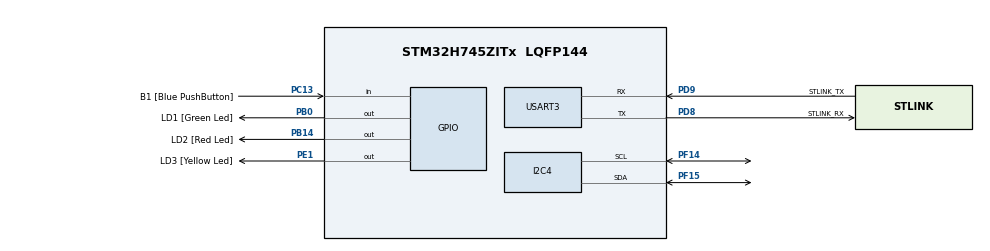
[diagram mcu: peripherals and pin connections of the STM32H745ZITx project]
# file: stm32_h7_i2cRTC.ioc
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CortexM4.IPs=BDMA,CORTEX_M4\:I,DEBUG,DMA,FATFS_M4\:I,FREERTOS_M4\:I,GPIO,IWDG2\:I,MDMA,NVIC2\:I,OPENAMP_M4\:I,PDM2PCM_M4\:I,PWR,RCC,RESMGR_UTILITY,SYS_M4\:I,USB_DEVICE_M4\:I,USB_HOST_M4\:I,VREFBUF,WWDG2\:I,USART3,I2C4
CortexM4.Pins=PE1
CortexM7.IPs=BDMA\:I,CORTEX_M7\:I,DEBUG\:I,DMA\:I,FATFS_M7\:I,FREERTOS_M7\:I,GPIO\:I,IWDG1\:I,MDMA\:I,NVIC1\:I,OPENAMP_M7\:I,PDM2PCM_M7\:I,PWR\:I,RCC\:I,RESMGR_UTILITY\:I,SYS\:I,USB_DEVICE_M7\:I,USB_HOST_M7\:I,VREFBUF\:I,WWDG1\:I,USART3\:I,I2C4\:I
CortexM7.Pins=PC13,PB0,PB14
I2C4.Timing=0x307075B1
Mcu.Family=STM32H7
Mcu.Name=STM32H745ZITx
Mcu.Package=LQFP144
NVIC1.PriorityGroup=NVIC_PRIORITYGROUP_4
NVIC2.PriorityGroup=NVIC_PRIORITYGROUP_4
PA13\ (JTMS/SWDIO).Mode=Serial_Wire
PA13\ (JTMS/SWDIO).PinAttribute=CortexM7
PA13\ (JTMS/SWDIO).Signal=DEBUG_JTMS-SWDIO
PA14\ (JTCK/SWCLK).Mode=Serial_Wire
PA14\ (JTCK/SWCLK).PinAttribute=CortexM7
PA14\ (JTCK/SWCLK).Signal=DEBUG_JTCK-SWCLK
PB0.GPIO_Label=LD1 [Green Led]
PB0.PinAttribute=CortexM7
PB0.Signal=GPIO_Output
PB14.GPIO_Label=LD2 [Red Led]
PB14.PinAttribute=CortexM7
PB14.Signal=GPIO_Output
PC13.GPIO_Label=B1 [Blue PushButton]
PC13.PinAttribute=CortexM7
PC13.Signal=GPIO_Input
PC14-OSC32_IN\ (OSC32_IN).Mode=LSE-External-Oscillator
PC14-OSC32_IN\ (OSC32_IN).PinAttribute=CortexM7
PC14-OSC32_IN\ (OSC32_IN).Signal=RCC_OSC32_IN
PC15-OSC32_OUT\ (OSC32_OUT).Mode=LSE-External-Oscillator
PC15-OSC32_OUT\ (OSC32_OUT).PinAttribute=CortexM7
PC15-OSC32_OUT\ (OSC32_OUT).Signal=RCC_OSC32_OUT
PD8.GPIO_Label=STLINK_RX
PD8.Mode=Asynchronous
PD8.PinAttribute=CortexM7
PD8.Signal=USART3_TX
PD9.GPIO_Label=STLINK_TX
PD9.Mode=Asynchronous
PD9.PinAttribute=CortexM7
PD9.Signal=USART3_RX
PE1.GPIO_Label=LD3 [Yellow Led]
PE1.PinAttribute=CortexM4
PE1.Signal=GPIO_Output
PF14.Mode=I2C
PF14.PinAttribute=CortexM7
PF14.Signal=I2C4_SCL
PF15.Mode=I2C
PF15.PinAttribute=CortexM7
PF15.Signal=I2C4_SDA
PH0-OSC_IN\ (PH0).Mode=HSE-External-Clock-Source
PH0-OSC_IN\ (PH0).PinAttribute=CortexM7
PH0-OSC_IN\ (PH0).Signal=RCC_OSC_IN
ProjectManager.HeapSize=M4-0x200,M7-0x200
ProjectManager.StackSize=M4-0x400,M7-0x400
ProjectManager.TargetToolchain=STM32CubeIDE
RCC.ADCFreq_Value=16125000
RCC.APB1Freq_Value=120000000
RCC.APB2Freq_Value=120000000
RCC.APB3Freq_Value=120000000
RCC.APB4Freq_Value=120000000
RCC.CortexFreq_Value=480000000
RCC.D1PPRE=RCC_APB3_DIV2
RCC.D2PPRE1=RCC_APB1_DIV2
RCC.D2PPRE2=RCC_APB2_DIV2
RCC.D3PPRE=RCC_APB4_DIV2
RCC.DIVM1=2
RCC.DIVN1=240
RCC.HCLKFreq_Value=240000000
RCC.HPRE=RCC_HCLK_DIV2
RCC.HSE_VALUE=8000000
RCC.PLLSourceVirtual=RCC_PLLSOURCE_HSE
RCC.SYSCLKFreq_VALUE=480000000
RCC.SYSCLKSource=RCC_SYSCLKSOURCE_PLLCLK
RCC.USBFreq_Value=480000000
SYS.userName=SYS_M7
USART3.VirtualMode-Asynchronous=VM_ASYNC
VP_SYS_M4_VS_Systick.Mode=SysTick
board=custom

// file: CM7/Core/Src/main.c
/* USER CODE BEGIN Header */
/**
 ******************************************************************************
 * @file           : main.c
 * @brief          : Main program body
 ******************************************************************************
 * @attention
 *
 * Copyright (c) 2022 STMicroelectronics.
 * All rights reserved.
 *
 * This software is licensed under terms that can be found in the LICENSE file
 * in the root directory of this software component.
 * If no LICENSE file comes with this software, it is provided AS-IS.
 *
 ******************************************************************************
 */
/* USER CODE END Header */
#include "main.h"

/* USER CODE BEGIN Includes */
#include "myprintf.h"
#include "RTC_lib.h"
/* USER CODE END Includes */

/* USER CODE BEGIN PD */

#ifndef HSEM_ID_0
#define HSEM_ID_0 (0U) /* HW semaphore 0*/
#endif
/* USER CODE END PD */

I2C_HandleTypeDef hi2c4;

UART_HandleTypeDef huart3;

void SystemClock_Config(void);
static void MX_GPIO_Init(void);
static void MX_USART3_UART_Init(void);
static void MX_I2C4_Init(void);

int main(void) {
	/* USER CODE BEGIN Boot_Mode_Sequence_0 */
	int32_t timeout;
	/* USER CODE END Boot_Mode_Sequence_0 */

	/* USER CODE BEGIN Boot_Mode_Sequence_1 */
	/* Wait until CPU2 boots and enters in stop mode or timeout*/
	timeout = 0xFFFF;
	while ((__HAL_RCC_GET_FLAG(RCC_FLAG_D2CKRDY) != RESET) && (timeout-- > 0))
		;
	if (timeout < 0) {
		Error_Handler();
	}
	/* USER CODE END Boot_Mode_Sequence_1 */
	/* MCU Configuration--------------------------------------------------------*/

	/* Reset of all peripherals, Initializes the Flash interface and the Systick. */
	HAL_Init();

	/* Configure the system clock */
	SystemClock_Config();
	/* USER CODE BEGIN Boot_Mode_Sequence_2 */
	/* When system initialization is finished, Cortex-M7 will release Cortex-M4 by means of
	 HSEM notification */
	/*HW semaphore Clock enable*/
	__HAL_RCC_HSEM_CLK_ENABLE();
	/*Take HSEM */
	HAL_HSEM_FastTake(HSEM_ID_0);
	/*Release HSEM in order to notify the CPU2(CM4)*/
	HAL_HSEM_Release(HSEM_ID_0, 0);
	/* wait until CPU2 wakes up from stop mode */
	timeout = 0xFFFF;
	while ((__HAL_RCC_GET_FLAG(RCC_FLAG_D2CKRDY) == RESET) && (timeout-- > 0))
		;
	if (timeout < 0) {
		Error_Handler();
	}
	/* USER CODE END Boot_Mode_Sequence_2 */

	/* Initialize all configured peripherals */
	MX_GPIO_Init();
	MX_USART3_UART_Init();
	MX_I2C4_Init();

	/* Infinite loop */
	/* USER CODE BEGIN WHILE */

	uint16_t RTC_ADDR = 0b1101000;
	uint8_t curr_time[7];

	SetTime(RTC_ADDR, 0, 28, 18, 7, 10, 22);
	printf("TIME SET\n\r");
	while (1) {

//
		HAL_I2C_Mem_Read(&hi2c4, RTC_ADDR << 1, 0x00, I2C_MEMADD_SIZE_8BIT,
				&curr_time, sizeof(curr_time), HAL_MAX_DELAY);

		printCurrentTime(curr_time, sizeof(curr_time));
//		uint8_t data = 0x03;
//		HAL_I2C_Mem_Write(&hi2c4, RTC_ADDR << 1, 0x01, I2C_MEMADD_SIZE_8BIT, &data,
//					1, HAL_MAX_DELAY);
		HAL_GPIO_TogglePin(LD1_GPIO_Port, LD1_Pin);
		HAL_Delay(100);
		/* USER CODE END WHILE */

	}
}

void SystemClock_Config(void) {
	RCC_OscInitTypeDef RCC_OscInitStruct = { 0 };
	RCC_ClkInitTypeDef RCC_ClkInitStruct = { 0 };

	/** Supply configuration update enable
	 */
	HAL_PWREx_ConfigSupply(PWR_DIRECT_SMPS_SUPPLY);

	/** Configure the main internal regulator output voltage
	 */
	__HAL_PWR_VOLTAGESCALING_CONFIG(PWR_REGULATOR_VOLTAGE_SCALE0);

	while (!__HAL_PWR_GET_FLAG(PWR_FLAG_VOSRDY)) {
	}

	/** Initializes the RCC Oscillators according to the specified parameters
	 * in the RCC_OscInitTypeDef structure.
	 */
	RCC_OscInitStruct.OscillatorType = RCC_OSCILLATORTYPE_HSE;
	RCC_OscInitStruct.HSEState = RCC_HSE_BYPASS;
	RCC_OscInitStruct.PLL.PLLState = RCC_PLL_ON;
	RCC_OscInitStruct.PLL.PLLSource = RCC_PLLSOURCE_HSE;
	RCC_OscInitStruct.PLL.PLLM = 2;
	RCC_OscInitStruct.PLL.PLLN = 240;
	RCC_OscInitStruct.PLL.PLLP = 2;
	RCC_OscInitStruct.PLL.PLLQ = 2;
	RCC_OscInitStruct.PLL.PLLR = 2;
	RCC_OscInitStruct.PLL.PLLRGE = RCC_PLL1VCIRANGE_2;
	RCC_OscInitStruct.PLL.PLLVCOSEL = RCC_PLL1VCOWIDE;
	RCC_OscInitStruct.PLL.PLLFRACN = 0;
	if (HAL_RCC_OscConfig(&RCC_OscInitStruct) != HAL_OK) {
		Error_Handler();
	}

	/** Initializes the CPU, AHB and APB buses clocks
	 */
	RCC_ClkInitStruct.ClockType = RCC_CLOCKTYPE_HCLK | RCC_CLOCKTYPE_SYSCLK
			| RCC_CLOCKTYPE_PCLK1 | RCC_CLOCKTYPE_PCLK2 | RCC_CLOCKTYPE_D3PCLK1
			| RCC_CLOCKTYPE_D1PCLK1;
	RCC_ClkInitStruct.SYSCLKSource = RCC_SYSCLKSOURCE_PLLCLK;
	RCC_ClkInitStruct.SYSCLKDivider = RCC_SYSCLK_DIV1;
	RCC_ClkInitStruct.AHBCLKDivider = RCC_HCLK_DIV2;
	RCC_ClkInitStruct.APB3CLKDivider = RCC_APB3_DIV2;
	RCC_ClkInitStruct.APB1CLKDivider = RCC_APB1_DIV2;
	RCC_ClkInitStruct.APB2CLKDivider = RCC_APB2_DIV2;
	RCC_ClkInitStruct.APB4CLKDivider = RCC_APB4_DIV2;

	if (HAL_RCC_ClockConfig(&RCC_ClkInitStruct, FLASH_LATENCY_4) != HAL_OK) {
		Error_Handler();
	}
}

static void MX_I2C4_Init(void) {

	hi2c4.Instance = I2C4;
	hi2c4.Init.Timing = 0x307075B1;
	hi2c4.Init.OwnAddress1 = 0;
	hi2c4.Init.AddressingMode = I2C_ADDRESSINGMODE_7BIT;
	hi2c4.Init.DualAddressMode = I2C_DUALADDRESS_DISABLE;
	hi2c4.Init.OwnAddress2 = 0;
	hi2c4.Init.OwnAddress2Masks = I2C_OA2_NOMASK;
	hi2c4.Init.GeneralCallMode = I2C_GENERALCALL_DISABLE;
	hi2c4.Init.NoStretchMode = I2C_NOSTRETCH_DISABLE;
	if (HAL_I2C_Init(&hi2c4) != HAL_OK) {
		Error_Handler();
	}

	/** Configure Analogue filter
	 */
	if (HAL_I2CEx_ConfigAnalogFilter(&hi2c4, I2C_ANALOGFILTER_ENABLE)
			!= HAL_OK) {
		Error_Handler();
	}

	/** Configure Digital filter
	 */
	if (HAL_I2CEx_ConfigDigitalFilter(&hi2c4, 0) != HAL_OK) {
		Error_Handler();
	}

}

static void MX_USART3_UART_Init(void) {

	huart3.Instance = USART3;
	huart3.Init.BaudRate = 115200;
	huart3.Init.WordLength = UART_WORDLENGTH_8B;
	huart3.Init.StopBits = UART_STOPBITS_1;
	huart3.Init.Parity = UART_PARITY_NONE;
	huart3.Init.Mode = UART_MODE_TX_RX;
	huart3.Init.HwFlowCtl = UART_HWCONTROL_NONE;
	huart3.Init.OverSampling = UART_OVERSAMPLING_16;
	huart3.Init.OneBitSampling = UART_ONE_BIT_SAMPLE_DISABLE;
	huart3.Init.ClockPrescaler = UART_PRESCALER_DIV1;
	huart3.AdvancedInit.AdvFeatureInit = UART_ADVFEATURE_NO_INIT;
	if (HAL_UART_Init(&huart3) != HAL_OK) {
		Error_Handler();
	}
	if (HAL_UARTEx_SetTxFifoThreshold(&huart3,
	UART_TXFIFO_THRESHOLD_1_8) != HAL_OK) {
		Error_Handler();
	}
	if (HAL_UARTEx_SetRxFifoThreshold(&huart3,
	UART_RXFIFO_THRESHOLD_1_8) != HAL_OK) {
		Error_Handler();
	}
	if (HAL_UARTEx_DisableFifoMode(&huart3) != HAL_OK) {
		Error_Handler();
	}

}

static void MX_GPIO_Init(void) {
	GPIO_InitTypeDef GPIO_InitStruct = { 0 };

	/* GPIO Ports Clock Enable */
	__HAL_RCC_GPIOC_CLK_ENABLE();
	__HAL_RCC_GPIOH_CLK_ENABLE();
	__HAL_RCC_GPIOB_CLK_ENABLE();
	__HAL_RCC_GPIOF_CLK_ENABLE();
	__HAL_RCC_GPIOD_CLK_ENABLE();
	__HAL_RCC_GPIOA_CLK_ENABLE();

	/*Configure GPIO pin Output Level */
	HAL_GPIO_WritePin(GPIOB, LD1_Pin | LD2_Pin, GPIO_PIN_RESET);

	/*Configure GPIO pin : B1_Pin */
	GPIO_InitStruct.Pin = B1_Pin;
	GPIO_InitStruct.Mode = GPIO_MODE_INPUT;
	GPIO_InitStruct.Pull = GPIO_NOPULL;
	HAL_GPIO_Init(B1_GPIO_Port, &GPIO_InitStruct);

	/*Configure GPIO pins : LD1_Pin LD2_Pin */
	GPIO_InitStruct.Pin = LD1_Pin | LD2_Pin;
	GPIO_InitStruct.Mode = GPIO_MODE_OUTPUT_PP;
	GPIO_InitStruct.Pull = GPIO_NOPULL;
	GPIO_InitStruct.Speed = GPIO_SPEED_FREQ_LOW;
	HAL_GPIO_Init(GPIOB, &GPIO_InitStruct);

}

void Error_Handler(void) {
	__disable_irq();
	while (1) {
	}
}
